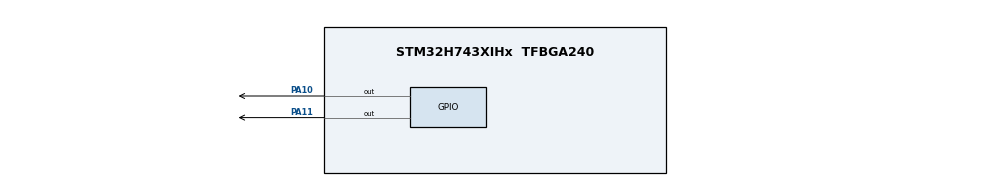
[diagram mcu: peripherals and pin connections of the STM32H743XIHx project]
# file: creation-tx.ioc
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CORTEX_M7.CPU_DCache=Enabled
CORTEX_M7.CPU_ICache=Enabled
CORTEX_M7.default_mode_Activation=1
Mcu.Family=STM32H7
Mcu.Name=STM32H743XIHx
Mcu.Package=TFBGA240
NVIC.PriorityGroup=NVIC_PRIORITYGROUP_4
NVIC.TIM6_DAC_IRQn=true\:15\:0\:false\:false\:true\:false\:true\:true
NVIC.TimeBase=TIM6_DAC_IRQn
NVIC.TimeBaseIP=TIM6
PA10.GPIO_Speed=GPIO_SPEED_FREQ_HIGH
PA10.PinState=GPIO_PIN_SET
PA10.Signal=GPIO_Output
PA11.GPIO_Speed=GPIO_SPEED_FREQ_HIGH
PA11.PinState=GPIO_PIN_SET
PA11.Signal=GPIO_Output
PH0-OSC_IN\ (PH0).Mode=HSE-External-Clock-Source
PH0-OSC_IN\ (PH0).Signal=RCC_OSC_IN
ProjectManager.HeapSize=0x200
ProjectManager.StackSize=0x400
ProjectManager.TargetToolchain=STM32CubeIDE
RCC.ADCFreq_Value=129000000
RCC.APB1Freq_Value=64000000
RCC.APB2Freq_Value=64000000
RCC.APB3Freq_Value=64000000
RCC.APB4Freq_Value=64000000
RCC.CortexFreq_Value=64000000
RCC.HCLKFreq_Value=64000000
RCC.PWR_Regulator_Voltage_Scale=PWR_REGULATOR_VOLTAGE_SCALE1
RCC.SYSCLKFreq_VALUE=64000000
RCC.USBFreq_Value=129000000
VP_SYS_VS_tim6.Mode=TIM6
board=STM32H743I-EVAL2

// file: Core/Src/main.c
/* USER CODE BEGIN Header */
/**
  ******************************************************************************
  * @file           : main.c
  * @brief          : Main program body
  ******************************************************************************
  * @attention
  *
  * Copyright (c) 2024 STMicroelectronics.
  * All rights reserved.
  *
  * This software is licensed under terms that can be found in the LICENSE file
  * in the root directory of this software component.
  * If no LICENSE file comes with this software, it is provided AS-IS.
  *
  ******************************************************************************
  */
/* USER CODE END Header */
#include "main.h"

void SystemClock_Config(void);
static void MPU_Initialize(void);
static void MPU_Config(void);
static void MX_GPIO_Init(void);

int main(void)
{

  /* Enable I-Cache---------------------------------------------------------*/
  SCB_EnableICache();

  /* Enable D-Cache---------------------------------------------------------*/
  SCB_EnableDCache();

  /* MCU Configuration--------------------------------------------------------*/

  /* Reset of all peripherals, Initializes the Flash interface and the Systick. */
  HAL_Init();

  /* MPU Configuration--------------------------------------------------------*/
  MPU_Config();

  /* Configure the system clock */
  SystemClock_Config();

  /* Initialize all configured peripherals */
  MX_GPIO_Init();
  /* USER CODE BEGIN 2 */
  BSP_LED_Init(LED1);
  BSP_LED_Init(LED2);
  BSP_LED_Init(LED3);

  /* USER CODE END 2 */

  /* Infinite loop */
  while (1)
  {

  }
}

void SystemClock_Config(void)
{
  RCC_OscInitTypeDef RCC_OscInitStruct = {0};
  RCC_ClkInitTypeDef RCC_ClkInitStruct = {0};

  /** Supply configuration update enable
  */
  HAL_PWREx_ConfigSupply(PWR_LDO_SUPPLY);

  /** Configure the main internal regulator output voltage
  */
  __HAL_PWR_VOLTAGESCALING_CONFIG(PWR_REGULATOR_VOLTAGE_SCALE1);

  while(!__HAL_PWR_GET_FLAG(PWR_FLAG_VOSRDY)) {}

  /** Initializes the RCC Oscillators according to the specified parameters
  * in the RCC_OscInitTypeDef structure.
  */
  RCC_OscInitStruct.OscillatorType = RCC_OSCILLATORTYPE_HSI;
  RCC_OscInitStruct.HSIState = RCC_HSI_DIV1;
  RCC_OscInitStruct.HSICalibrationValue = RCC_HSICALIBRATION_DEFAULT;
  RCC_OscInitStruct.PLL.PLLState = RCC_PLL_NONE;
  if (HAL_RCC_OscConfig(&RCC_OscInitStruct) != HAL_OK)
  {
    Error_Handler();
  }

  /** Initializes the CPU, AHB and APB buses clocks
  */
  RCC_ClkInitStruct.ClockType = RCC_CLOCKTYPE_HCLK|RCC_CLOCKTYPE_SYSCLK
                              |RCC_CLOCKTYPE_PCLK1|RCC_CLOCKTYPE_PCLK2
                              |RCC_CLOCKTYPE_D3PCLK1|RCC_CLOCKTYPE_D1PCLK1;
  RCC_ClkInitStruct.SYSCLKSource = RCC_SYSCLKSOURCE_HSI;
  RCC_ClkInitStruct.SYSCLKDivider = RCC_SYSCLK_DIV1;
  RCC_ClkInitStruct.AHBCLKDivider = RCC_HCLK_DIV1;
  RCC_ClkInitStruct.APB3CLKDivider = RCC_APB3_DIV1;
  RCC_ClkInitStruct.APB1CLKDivider = RCC_APB1_DIV1;
  RCC_ClkInitStruct.APB2CLKDivider = RCC_APB2_DIV1;
  RCC_ClkInitStruct.APB4CLKDivider = RCC_APB4_DIV1;

  if (HAL_RCC_ClockConfig(&RCC_ClkInitStruct, FLASH_LATENCY_0) != HAL_OK)
  {
    Error_Handler();
  }
}

static void MX_GPIO_Init(void)
{
  GPIO_InitTypeDef GPIO_InitStruct = {0};

  /* GPIO Ports Clock Enable */
  __HAL_RCC_GPIOA_CLK_ENABLE();
  __HAL_RCC_GPIOH_CLK_ENABLE();

  /*Configure GPIO pin Output Level */
  HAL_GPIO_WritePin(GPIOA, GPIO_PIN_10|GPIO_PIN_11, GPIO_PIN_SET);

  /*Configure GPIO pins : PA10 PA11 */
  GPIO_InitStruct.Pin = GPIO_PIN_10|GPIO_PIN_11;
  GPIO_InitStruct.Mode = GPIO_MODE_OUTPUT_PP;
  GPIO_InitStruct.Pull = GPIO_NOPULL;
  GPIO_InitStruct.Speed = GPIO_SPEED_FREQ_HIGH;
  HAL_GPIO_Init(GPIOA, &GPIO_InitStruct);

}

/* MPU Configuration */

void MPU_Config(void)
{
  MPU_Region_InitTypeDef MPU_InitStruct = {0};

  /* Disables the MPU */
  HAL_MPU_Disable();

  /** Initializes and configures the Region and the memory to be protected
  */
  MPU_InitStruct.Enable = MPU_REGION_ENABLE;
  MPU_InitStruct.Number = MPU_REGION_NUMBER0;
  MPU_InitStruct.BaseAddress = 0x0;
  MPU_InitStruct.Size = MPU_REGION_SIZE_4GB;
  MPU_InitStruct.SubRegionDisable = 0x87;
  MPU_InitStruct.TypeExtField = MPU_TEX_LEVEL0;
  MPU_InitStruct.AccessPermission = MPU_REGION_NO_ACCESS;
  MPU_InitStruct.DisableExec = MPU_INSTRUCTION_ACCESS_DISABLE;
  MPU_InitStruct.IsShareable = MPU_ACCESS_SHAREABLE;
  MPU_InitStruct.IsCacheable = MPU_ACCESS_NOT_CACHEABLE;
  MPU_InitStruct.IsBufferable = MPU_ACCESS_NOT_BUFFERABLE;

  HAL_MPU_ConfigRegion(&MPU_InitStruct);
  /* Enables the MPU */
  HAL_MPU_Enable(MPU_PRIVILEGED_DEFAULT);

}

void HAL_TIM_PeriodElapsedCallback(TIM_HandleTypeDef *htim)
{
  if (htim->Instance == TIM6) {
    HAL_IncTick();
  }
}

void Error_Handler(void)
{
  __disable_irq();
  while (1)
  {
  }
}
